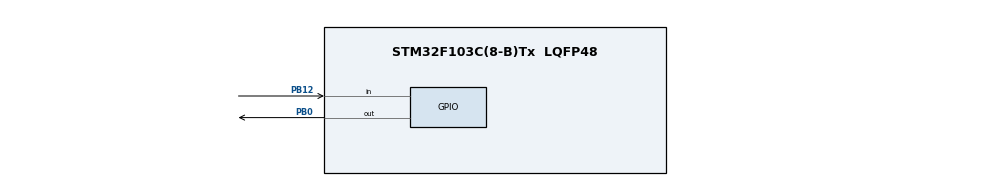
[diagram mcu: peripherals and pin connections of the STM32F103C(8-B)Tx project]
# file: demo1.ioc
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FREERTOS.Events01=KeyEvent,Dynamic,NULL
FREERTOS.Queues01=LEDQueue,16,uint32_t,0,Dynamic,NULL,NULL
FREERTOS.Tasks01=NumTask,24,128,StartNumTask,Default,NULL,Dynamic,NULL,NULL;KeyTask,40,128,StartKeyTask,Default,NULL,Dynamic,NULL,NULL;LightTask,16,128,StartLightTask,Default,NULL,Dynamic,NULL,NULL;JudgeTask0,32,128,StartJudgeTask,Default,NULL,Dynamic,NULL,NULL
Mcu.Family=STM32F1
Mcu.Name=STM32F103C(8-B)Tx
Mcu.Package=LQFP48
NVIC.PriorityGroup=NVIC_PRIORITYGROUP_4
NVIC.TIM4_IRQn=true\:15\:0\:false\:false\:true\:false\:false\:true\:true
NVIC.TimeBase=TIM4_IRQn
NVIC.TimeBaseIP=TIM4
PA13.Mode=Serial_Wire
PA13.Signal=SYS_JTMS-SWDIO
PA14.Mode=Serial_Wire
PA14.Signal=SYS_JTCK-SWCLK
PB0.Signal=GPIO_Output
PB12.Signal=GPIO_Input
ProjectManager.HeapSize=0x200
ProjectManager.StackSize=0x400
ProjectManager.TargetToolchain=MDK-ARM V5.32
RCC.APB1Freq_Value=8000000
RCC.APB2Freq_Value=8000000
VP_FREERTOS_VS_CMSIS_V2.Mode=CMSIS_V2
VP_SYS_VS_tim4.Mode=TIM4
board=custom

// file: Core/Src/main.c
/* USER CODE BEGIN Header */
/**
  ******************************************************************************
  * @file           : main.c
  * @brief          : Main program body
  ******************************************************************************
  * @attention
  *
  * Copyright (c) 2026 STMicroelectronics.
  * All rights reserved.
  *
  * This software is licensed under terms that can be found in the LICENSE file
  * in the root directory of this software component.
  * If no LICENSE file comes with this software, it is provided AS-IS.
  *
  ******************************************************************************
  */
/* USER CODE END Header */
#include "main.h"
#include "cmsis_os.h"
#include "gpio.h"

void SystemClock_Config(void);
void MX_FREERTOS_Init(void);

int main(void)
{

  /* MCU Configuration--------------------------------------------------------*/

  /* Reset of all peripherals, Initializes the Flash interface and the Systick. */
  HAL_Init();

  /* Configure the system clock */
  SystemClock_Config();

  /* Initialize all configured peripherals */
  MX_GPIO_Init();

  /* Init scheduler */
  osKernelInitialize();

  /* Call init function for freertos objects (in cmsis_os2.c) */
  MX_FREERTOS_Init();

  /* Start scheduler */
  osKernelStart();

  /* We should never get here as control is now taken by the scheduler */

  /* Infinite loop */
  while (1)
  {

  }
}

void SystemClock_Config(void)
{
  RCC_OscInitTypeDef RCC_OscInitStruct = {0};
  RCC_ClkInitTypeDef RCC_ClkInitStruct = {0};

  /** Initializes the RCC Oscillators according to the specified parameters
  * in the RCC_OscInitTypeDef structure.
  */
  RCC_OscInitStruct.OscillatorType = RCC_OSCILLATORTYPE_HSI;
  RCC_OscInitStruct.HSIState = RCC_HSI_ON;
  RCC_OscInitStruct.HSICalibrationValue = RCC_HSICALIBRATION_DEFAULT;
  RCC_OscInitStruct.PLL.PLLState = RCC_PLL_NONE;
  if (HAL_RCC_OscConfig(&RCC_OscInitStruct) != HAL_OK)
  {
    Error_Handler();
  }

  /** Initializes the CPU, AHB and APB buses clocks
  */
  RCC_ClkInitStruct.ClockType = RCC_CLOCKTYPE_HCLK|RCC_CLOCKTYPE_SYSCLK
                              |RCC_CLOCKTYPE_PCLK1|RCC_CLOCKTYPE_PCLK2;
  RCC_ClkInitStruct.SYSCLKSource = RCC_SYSCLKSOURCE_HSI;
  RCC_ClkInitStruct.AHBCLKDivider = RCC_SYSCLK_DIV1;
  RCC_ClkInitStruct.APB1CLKDivider = RCC_HCLK_DIV1;
  RCC_ClkInitStruct.APB2CLKDivider = RCC_HCLK_DIV1;

  if (HAL_RCC_ClockConfig(&RCC_ClkInitStruct, FLASH_LATENCY_0) != HAL_OK)
  {
    Error_Handler();
  }
}

void HAL_TIM_PeriodElapsedCallback(TIM_HandleTypeDef *htim)
{
  if (htim->Instance == TIM4)
  {
    HAL_IncTick();
  }
}

void Error_Handler(void)
{
  __disable_irq();
  while (1)
  {
  }
}

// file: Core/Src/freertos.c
/* USER CODE BEGIN Header */
/**
  ******************************************************************************
  * File Name          : freertos.c
  * Description        : Code for freertos applications
  ******************************************************************************
  * @attention
  *
  * Copyright (c) 2026 STMicroelectronics.
  * All rights reserved.
  *
  * This software is licensed under terms that can be found in the LICENSE file
  * in the root directory of this software component.
  * If no LICENSE file comes with this software, it is provided AS-IS.
  *
  ******************************************************************************
  */
/* USER CODE END Header */

#include "FreeRTOS.h"
#include "task.h"
#include "main.h"
#include "cmsis_os.h"

/* USER CODE BEGIN PD */
#define flag (1<<0)
/* USER CODE END PD */

/* Definitions for NumTask */
osThreadId_t NumTaskHandle;
const osThreadAttr_t NumTask_attributes = {
  .name = "NumTask",
  .stack_size = 128 * 4,
  .priority = (osPriority_t) osPriorityNormal,
};
/* Definitions for KeyTask */
osThreadId_t KeyTaskHandle;
const osThreadAttr_t KeyTask_attributes = {
  .name = "KeyTask",
  .stack_size = 128 * 4,
  .priority = (osPriority_t) osPriorityHigh,
};
/* Definitions for LightTask */
osThreadId_t LightTaskHandle;
const osThreadAttr_t LightTask_attributes = {
  .name = "LightTask",
  .stack_size = 128 * 4,
  .priority = (osPriority_t) osPriorityBelowNormal,
};
/* Definitions for JudgeTask0 */
osThreadId_t JudgeTask0Handle;
const osThreadAttr_t JudgeTask0_attributes = {
  .name = "JudgeTask0",
  .stack_size = 128 * 4,
  .priority = (osPriority_t) osPriorityAboveNormal,
};
/* Definitions for LEDQueue */
osMessageQueueId_t LEDQueueHandle;
const osMessageQueueAttr_t LEDQueue_attributes = {
  .name = "LEDQueue"
};
/* Definitions for KeyEvent */
osEventFlagsId_t KeyEventHandle;
const osEventFlagsAttr_t KeyEvent_attributes = {
  .name = "KeyEvent"
};

void StartNumTask(void *argument);
void StartKeyTask(void *argument);
void StartLightTask(void *argument);
void StartJudgeTask(void *argument);

void MX_FREERTOS_Init(void); /* (MISRA C 2004 rule 8.1) */

void MX_FREERTOS_Init(void) {

  /* Create the queue(s) */
  /* creation of LEDQueue */
  LEDQueueHandle = osMessageQueueNew (16, sizeof(uint32_t), &LEDQueue_attributes);

  /* Create the thread(s) */
  /* creation of NumTask */
  NumTaskHandle = osThreadNew(StartNumTask, NULL, &NumTask_attributes);

  /* creation of KeyTask */
  KeyTaskHandle = osThreadNew(StartKeyTask, NULL, &KeyTask_attributes);

  /* creation of LightTask */
  LightTaskHandle = osThreadNew(StartLightTask, NULL, &LightTask_attributes);

  /* creation of JudgeTask0 */
  JudgeTask0Handle = osThreadNew(StartJudgeTask, NULL, &JudgeTask0_attributes);

  /* Create the event(s) */
  /* creation of KeyEvent */
  KeyEventHandle = osEventFlagsNew(&KeyEvent_attributes);

}

void StartNumTask(void *argument)
{
  /* USER CODE BEGIN StartNumTask */
  /* Infinite loop */
	uint32_t  count=0;
	uint32_t  led=1;
	uint32_t  data=0;

  for(;;)
  {
	if(count>5)
	{
		count=0;
		led=led+1;
		if(led>5)
		{
			led=1;
		}
	}
	else{
	count=count+1;
	}

	data=led*200;
	osMessageQueuePut(LEDQueueHandle,&data,0,osWaitForever);

    osDelay(100);
  }
  /* USER CODE END StartNumTask */
}

void StartKeyTask(void *argument)
{
  /* USER CODE BEGIN StartKeyTask */
	uint32_t btncount=0;
  /* Infinite loop */
  for(;;)
  {
	  if(HAL_GPIO_ReadPin(GPIOB,GPIO_PIN_12)==GPIO_PIN_RESET)
	  {
		  if(HAL_GPIO_ReadPin(GPIOB,GPIO_PIN_12)==GPIO_PIN_RESET)
		  {
			  btncount++;
			  if(btncount%2==1)
			  {
				  osEventFlagsSet(KeyEventHandle,flag);

			  }
			  else
			  {
				  osEventFlagsClear(KeyEventHandle,flag);
			  }
		  }
		  while(HAL_GPIO_ReadPin(GPIOB,GPIO_PIN_12)==GPIO_PIN_RESET)
		  {
			  osDelay(10);
		  }
	  }
	  else
	  {
		  osDelay(10);
	  }
  }
  /* USER CODE END StartKeyTask */
}

void StartLightTask(void *argument)
{
  /* USER CODE BEGIN StartLightTask */
	uint32_t data=0;
	uint16_t time=0;
  /* Infinite loop */
  for(;;)
  {
	osMessageQueueGet(LEDQueueHandle,&data,NULL,osWaitForever);

	HAL_GPIO_TogglePin(GPIOB,GPIO_PIN_0);
    osDelay(data);
  }
  /* USER CODE END StartLightTask */
}

void StartJudgeTask(void *argument)
{
  /* USER CODE BEGIN StartJudgeTask */
  /* Infinite loop */
  for(;;)
  {
	 if(osEventFlagsGet(KeyEventHandle)==1)
	 {
		 vTaskSuspend(LightTaskHandle);
	 }
	else
	{
		vTaskResume(LightTaskHandle);
	}

    osDelay(10);
  }
  /* USER CODE END StartJudgeTask */
}
